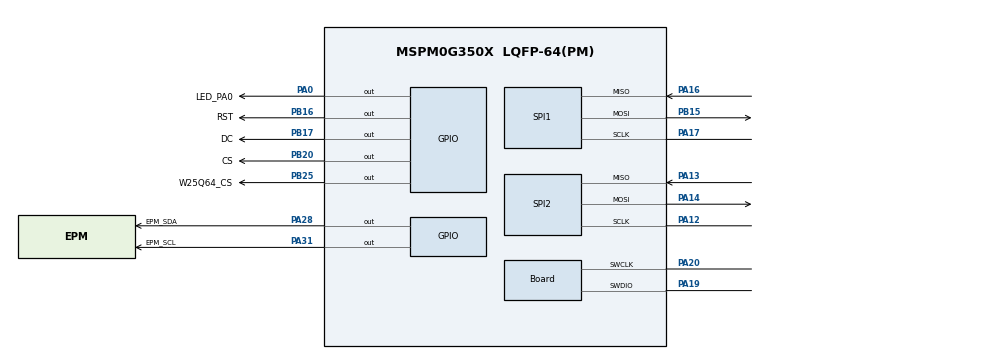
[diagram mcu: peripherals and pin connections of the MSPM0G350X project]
/**
 * @cliArgs --device "MSPM0G350X" --package "LQFP-64(PM)" --part "Default" --product "mspm0_sdk@2.00.01.00"
 * @versions {"tool":"1.20.0+3587"}
 */

/**
 * Import the modules used in this configuration.
 */
const GPIO          = scripting.addModule("/ti/driverlib/GPIO", {}, false);
const GPIO1         = GPIO.addInstance();
const GPIO2         = GPIO.addInstance();
const SPI           = scripting.addModule("/ti/driverlib/SPI", {}, false);
const SPI1          = SPI.addInstance();
const SPI2          = SPI.addInstance();
const SYSCTL        = scripting.addModule("/ti/driverlib/SYSCTL");
const SYSTICK       = scripting.addModule("/ti/driverlib/SYSTICK");
const ProjectConfig = scripting.addModule("/ti/project_config/ProjectConfig");

/**
 * Write custom configuration values to the imported modules.
 */
GPIO1.port                          = "PORTA";
GPIO1.$name                         = "USER_GPIO";
GPIO1.associatedPins.create(3);
GPIO1.associatedPins[0].$name       = "LED_PA0";
GPIO1.associatedPins[0].pin.$assign = "PA0";
GPIO1.associatedPins[1].$name       = "EPM_SCL";
GPIO1.associatedPins[1].pin.$assign = "PA31";
GPIO1.associatedPins[2].$name       = "EPM_SDA";
GPIO1.associatedPins[2].pin.$assign = "PA28";

const Board                       = scripting.addModule("/ti/driverlib/Board", {}, false);
Board.peripheral.$assign          = "DEBUGSS";
Board.peripheral.swclkPin.$assign = "PA20";
Board.peripheral.swdioPin.$assign = "PA19";

GPIO2.$name                         = "PORTB";
GPIO2.associatedPins.create(4);
GPIO2.associatedPins[0].$name       = "RST";
GPIO2.associatedPins[0].pin.$assign = "PB16";
GPIO2.associatedPins[1].$name       = "DC";
GPIO2.associatedPins[1].pin.$assign = "PB17";
GPIO2.associatedPins[2].$name       = "CS";
GPIO2.associatedPins[2].pin.$assign = "PB20";
GPIO2.associatedPins[3].$name       = "W25Q64_CS";
GPIO2.associatedPins[3].pin.$assign = "PB25";

SPI1.$name                      = "SPI_0";
SPI1.targetBitRate              = 1000000;
SPI1.frameFormat                = "MOTO3";
SPI1.polarity                   = "1";
SPI1.phase                      = "1";
SPI1.peripheral.$assign         = "SPI1";
SPI1.peripheral.sclkPin.$assign = "PA17";
SPI1.peripheral.mosiPin.$assign = "PB15";
SPI1.peripheral.misoPin.$assign = "PA16";
SPI1.sclkPinConfig.$name        = "ti_driverlib_gpio_GPIOPinGeneric2";
SPI1.mosiPinConfig.$name        = "ti_driverlib_gpio_GPIOPinGeneric3";
SPI1.misoPinConfig.$name        = "ti_driverlib_gpio_GPIOPinGeneric4";

SPI2.$name                              = "SPI_1";
SPI2.targetBitRate                      = 1000000;
SPI2.frameFormat                        = "MOTO3";
SPI2.chipSelect                         = [];
SPI2.enableDMAEvent1                    = false;
SPI2.enableDMAEvent2                    = false;
SPI2.spiClkSrc                          = "BUSCLK";
SPI2.peripheral.$assign                 = "SPI0";
SPI2.peripheral.sclkPin.$assign         = "PA12";
SPI2.peripheral.mosiPin.$assign         = "PA14";
SPI2.peripheral.misoPin.$assign         = "PA13";
SPI2.sclkPinConfig.$name                = "ti_driverlib_gpio_GPIOPinGeneric0";
SPI2.sclkPinConfig.direction            = scripting.forceWrite("OUTPUT");
SPI2.sclkPinConfig.onlyInternalResistor = scripting.forceWrite(false);
SPI2.sclkPinConfig.passedPeripheralType = scripting.forceWrite("Digital");
SPI2.mosiPinConfig.$name                = "ti_driverlib_gpio_GPIOPinGeneric1";
SPI2.mosiPinConfig.direction            = scripting.forceWrite("OUTPUT");
SPI2.mosiPinConfig.hideOutputInversion  = scripting.forceWrite(false);
SPI2.mosiPinConfig.onlyInternalResistor = scripting.forceWrite(false);
SPI2.mosiPinConfig.passedPeripheralType = scripting.forceWrite("Digital");
SPI2.misoPinConfig.$name                = "ti_driverlib_gpio_GPIOPinGeneric5";
SPI2.misoPinConfig.onlyInternalResistor = scripting.forceWrite(false);
SPI2.misoPinConfig.passedPeripheralType = scripting.forceWrite("Digital");

SYSCTL.clockTreeEn = true;

SYSTICK.periodEnable      = true;
SYSTICK.interruptEnable   = true;
SYSTICK.interruptPriority = "0";
SYSTICK.systickEnable     = true;
SYSTICK.period            = 32000;

ProjectConfig.deviceSpin = "MSPM0G3507";
